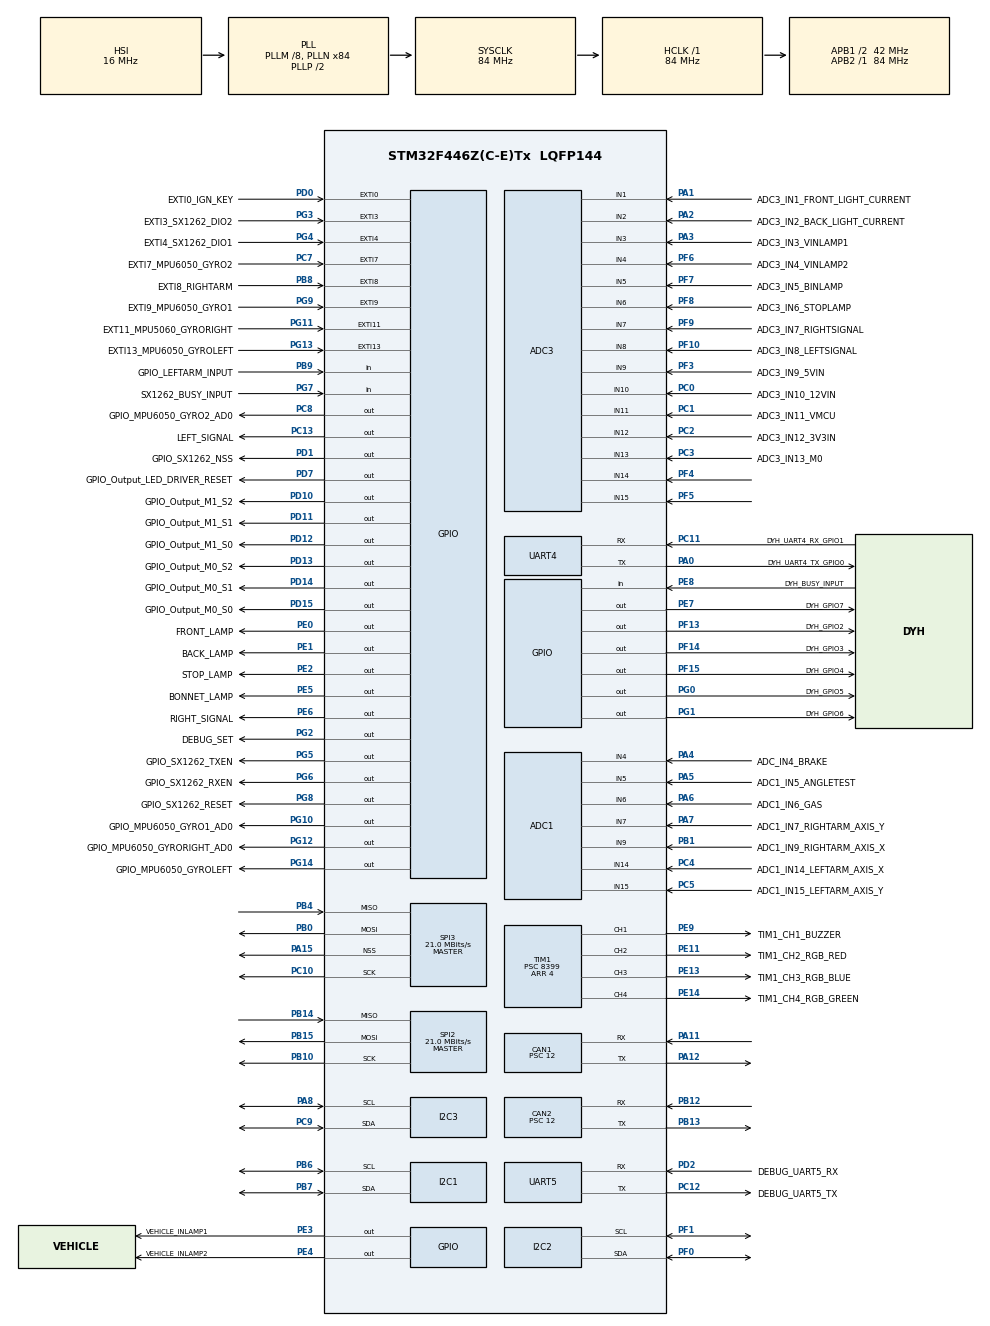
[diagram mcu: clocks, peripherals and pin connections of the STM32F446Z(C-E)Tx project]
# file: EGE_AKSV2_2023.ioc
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ADC1.Channel-1\#ChannelRegularConversion=ADC_CHANNEL_4
ADC1.Channel-2\#ChannelRegularConversion=ADC_CHANNEL_4
ADC1.Channel-3\#ChannelRegularConversion=ADC_CHANNEL_4
ADC1.Channel-4\#ChannelRegularConversion=ADC_CHANNEL_4
ADC1.Channel-5\#ChannelRegularConversion=ADC_CHANNEL_4
ADC1.Channel-6\#ChannelRegularConversion=ADC_CHANNEL_4
ADC1.Channel-7\#ChannelRegularConversion=ADC_CHANNEL_4
ADC1.ContinuousConvMode=DISABLE
ADC1.NbrOfConversion=7
ADC1.NbrOfConversionFlag=1
ADC1.Rank-1\#ChannelRegularConversion=1
ADC1.Rank-2\#ChannelRegularConversion=2
ADC1.Rank-3\#ChannelRegularConversion=3
ADC1.Rank-4\#ChannelRegularConversion=4
ADC1.Rank-5\#ChannelRegularConversion=5
ADC1.Rank-6\#ChannelRegularConversion=6
ADC1.Rank-7\#ChannelRegularConversion=7
ADC1.SamplingTime-1\#ChannelRegularConversion=ADC_SAMPLETIME_28CYCLES
ADC1.SamplingTime-2\#ChannelRegularConversion=ADC_SAMPLETIME_3CYCLES
ADC1.SamplingTime-3\#ChannelRegularConversion=ADC_SAMPLETIME_3CYCLES
ADC1.SamplingTime-4\#ChannelRegularConversion=ADC_SAMPLETIME_3CYCLES
ADC1.SamplingTime-5\#ChannelRegularConversion=ADC_SAMPLETIME_3CYCLES
ADC1.SamplingTime-6\#ChannelRegularConversion=ADC_SAMPLETIME_3CYCLES
ADC1.SamplingTime-7\#ChannelRegularConversion=ADC_SAMPLETIME_3CYCLES
ADC1.ScanConvMode=ENABLE
ADC1.master=1
ADC3.Channel-1\#ChannelRegularConversion=ADC_CHANNEL_1
ADC3.Channel-10\#ChannelRegularConversion=ADC_CHANNEL_1
ADC3.Channel-11\#ChannelRegularConversion=ADC_CHANNEL_1
ADC3.Channel-12\#ChannelRegularConversion=ADC_CHANNEL_1
ADC3.Channel-13\#ChannelRegularConversion=ADC_CHANNEL_1
ADC3.Channel-14\#ChannelRegularConversion=ADC_CHANNEL_1
ADC3.Channel-15\#ChannelRegularConversion=ADC_CHANNEL_1
ADC3.Channel-2\#ChannelRegularConversion=ADC_CHANNEL_1
ADC3.Channel-3\#ChannelRegularConversion=ADC_CHANNEL_1
ADC3.Channel-4\#ChannelRegularConversion=ADC_CHANNEL_1
ADC3.Channel-5\#ChannelRegularConversion=ADC_CHANNEL_1
ADC3.Channel-6\#ChannelRegularConversion=ADC_CHANNEL_1
ADC3.Channel-7\#ChannelRegularConversion=ADC_CHANNEL_1
ADC3.Channel-8\#ChannelRegularConversion=ADC_CHANNEL_1
ADC3.Channel-9\#ChannelRegularConversion=ADC_CHANNEL_1
ADC3.ContinuousConvMode=DISABLE
ADC3.NbrOfConversion=15
ADC3.NbrOfConversionFlag=1
ADC3.Rank-1\#ChannelRegularConversion=1
ADC3.Rank-10\#ChannelRegularConversion=10
ADC3.Rank-11\#ChannelRegularConversion=11
ADC3.Rank-12\#ChannelRegularConversion=12
ADC3.Rank-13\#ChannelRegularConversion=13
ADC3.Rank-14\#ChannelRegularConversion=14
ADC3.Rank-15\#ChannelRegularConversion=15
ADC3.Rank-2\#ChannelRegularConversion=2
ADC3.Rank-3\#ChannelRegularConversion=3
ADC3.Rank-4\#ChannelRegularConversion=4
ADC3.Rank-5\#ChannelRegularConversion=5
ADC3.Rank-6\#ChannelRegularConversion=6
ADC3.Rank-7\#ChannelRegularConversion=7
ADC3.Rank-8\#ChannelRegularConversion=8
ADC3.Rank-9\#ChannelRegularConversion=9
ADC3.SamplingTime-1\#ChannelRegularConversion=ADC_SAMPLETIME_3CYCLES
ADC3.SamplingTime-10\#ChannelRegularConversion=ADC_SAMPLETIME_3CYCLES
ADC3.SamplingTime-11\#ChannelRegularConversion=ADC_SAMPLETIME_3CYCLES
ADC3.SamplingTime-12\#ChannelRegularConversion=ADC_SAMPLETIME_3CYCLES
ADC3.SamplingTime-13\#ChannelRegularConversion=ADC_SAMPLETIME_3CYCLES
ADC3.SamplingTime-14\#ChannelRegularConversion=ADC_SAMPLETIME_3CYCLES
ADC3.SamplingTime-15\#ChannelRegularConversion=ADC_SAMPLETIME_3CYCLES
ADC3.SamplingTime-2\#ChannelRegularConversion=ADC_SAMPLETIME_3CYCLES
ADC3.SamplingTime-3\#ChannelRegularConversion=ADC_SAMPLETIME_3CYCLES
ADC3.SamplingTime-4\#ChannelRegularConversion=ADC_SAMPLETIME_3CYCLES
ADC3.SamplingTime-5\#ChannelRegularConversion=ADC_SAMPLETIME_3CYCLES
ADC3.SamplingTime-6\#ChannelRegularConversion=ADC_SAMPLETIME_3CYCLES
ADC3.SamplingTime-7\#ChannelRegularConversion=ADC_SAMPLETIME_3CYCLES
ADC3.SamplingTime-8\#ChannelRegularConversion=ADC_SAMPLETIME_3CYCLES
ADC3.SamplingTime-9\#ChannelRegularConversion=ADC_SAMPLETIME_3CYCLES
ADC3.ScanConvMode=ENABLE
CAN1.BS1=CAN_BS1_11TQ
CAN1.BS2=CAN_BS2_2TQ
CAN1.CalculateBaudRate=250000
CAN1.CalculateTimeBit=4000
CAN1.CalculateTimeQuantum=285.7142857142857
CAN1.NART=ENABLE
CAN1.Prescaler=12
CAN2.BS1=CAN_BS1_11TQ
CAN2.BS2=CAN_BS2_2TQ
CAN2.CalculateBaudRate=250000
CAN2.CalculateTimeBit=4000
CAN2.CalculateTimeQuantum=285.7142857142857
CAN2.NART=ENABLE
CAN2.Prescaler=12
FREERTOS.Tasks01=defaultTask,24,128,StartDefaultTask,Default,NULL,Dynamic,NULL,NULL
Mcu.Family=STM32F4
Mcu.Name=STM32F446Z(C-E)Tx
Mcu.Package=LQFP144
NVIC.CAN1_RX0_IRQn=true\:5\:0\:false\:false\:true\:true\:true\:true\:true
NVIC.CAN1_RX1_IRQn=true\:5\:0\:false\:false\:true\:true\:true\:true\:true
NVIC.CAN1_SCE_IRQn=true\:5\:0\:false\:false\:true\:true\:true\:true\:true
NVIC.CAN1_TX_IRQn=true\:5\:0\:false\:false\:true\:true\:true\:true\:true
NVIC.EXTI0_IRQn=true\:5\:0\:false\:false\:true\:true\:true\:true\:true
NVIC.EXTI15_10_IRQn=true\:5\:0\:false\:false\:true\:true\:true\:true\:true
NVIC.EXTI3_IRQn=true\:5\:0\:false\:false\:true\:true\:true\:true\:true
NVIC.EXTI4_IRQn=true\:5\:0\:false\:false\:true\:true\:true\:true\:true
NVIC.EXTI9_5_IRQn=true\:5\:0\:false\:false\:true\:true\:true\:true\:true
NVIC.PriorityGroup=NVIC_PRIORITYGROUP_4
PA0-WKUP.GPIO_Label=DYH_UART4_TX_GPIO0
PA0-WKUP.Mode=Asynchronous
PA0-WKUP.Signal=UART4_TX
PA1.GPIO_Label=ADC3_IN1_FRONT_LIGHT_CURRENT
PA1.Signal=ADCx_IN1
PA11.Mode=CAN_Activate
PA11.Signal=CAN1_RX
PA12.Mode=CAN_Activate
PA12.Signal=CAN1_TX
PA13.Mode=Serial_Wire
PA13.Signal=SYS_JTMS-SWDIO
PA14.Mode=Serial_Wire
PA14.Signal=SYS_JTCK-SWCLK
PA15.Mode=NSS_Signal_Hard_Output
PA15.Signal=SPI3_NSS
PA2.GPIO_Label=ADC3_IN2_BACK_LIGHT_CURRENT
PA2.Signal=ADCx_IN2
PA3.GPIO_Label=ADC3_IN3_VINLAMP1
PA3.Signal=ADCx_IN3
PA4.GPIO_Label=ADC_IN4_BRAKE
PA4.Signal=ADCx_IN4
PA5.GPIO_Label=ADC1_IN5_ANGLETEST
PA5.Signal=ADCx_IN5
PA6.GPIO_Label=ADC1_IN6_GAS
PA6.Signal=ADCx_IN6
PA7.GPIO_Label=ADC1_IN7_RIGHTARM_AXIS_Y
PA7.Signal=ADCx_IN7
PA8.Mode=I2C
PA8.Signal=I2C3_SCL
PB0.Mode=Full_Duplex_Master
PB0.Signal=SPI3_MOSI
PB1.GPIO_Label=ADC1_IN9_RIGHTARM_AXIS_X
PB1.Signal=ADCx_IN9
PB10.Mode=Full_Duplex_Master
PB10.Signal=SPI2_SCK
PB12.Mode=CAN_Activate
PB12.Signal=CAN2_RX
PB13.Mode=CAN_Activate
PB13.Signal=CAN2_TX
PB14.Mode=Full_Duplex_Master
PB14.Signal=SPI2_MISO
PB15.Mode=Full_Duplex_Master
PB15.Signal=SPI2_MOSI
PB4.Mode=Full_Duplex_Master
PB4.Signal=SPI3_MISO
PB6.Mode=I2C
PB6.Signal=I2C1_SCL
PB7.Mode=I2C
PB7.Signal=I2C1_SDA
PB8.GPIO_Label=EXTI8_RIGHTARM
PB8.Signal=GPXTI8
PB9.GPIO_Label=GPIO_LEFTARM_INPUT
PB9.Signal=GPIO_Input
PC0.GPIO_Label=ADC3_IN10_12VIN
PC0.Signal=ADCx_IN10
PC1.GPIO_Label=ADC3_IN11_VMCU
PC1.Signal=ADCx_IN11
PC10.Mode=Full_Duplex_Master
PC10.Signal=SPI3_SCK
PC11.GPIO_Label=DYH_UART4_RX_GPIO1
PC11.Mode=Asynchronous
PC11.Signal=UART4_RX
PC12.GPIO_Label=DEBUG_UART5_TX
PC12.Mode=Asynchronous
PC12.Signal=UART5_TX
PC13.GPIO_Label=LEFT_SIGNAL
PC13.Signal=GPIO_Output
PC14-OSC32_IN.Mode=LSE-External-Oscillator
PC14-OSC32_IN.Signal=RCC_OSC32_IN
PC15-OSC32_OUT.Mode=LSE-External-Oscillator
PC15-OSC32_OUT.Signal=RCC_OSC32_OUT
PC2.GPIO_Label=ADC3_IN12_3V3IN
PC2.Signal=ADCx_IN12
PC3.GPIO_Label=ADC3_IN13_M0
PC3.Signal=ADCx_IN13
PC4.GPIO_Label=ADC1_IN14_LEFTARM_AXIS_X
PC4.Signal=ADCx_IN14
PC5.GPIO_Label=ADC1_IN15_LEFTARM_AXIS_Y
PC5.Signal=ADCx_IN15
PC7.GPIO_Label=EXTI7_MPU6050_GYRO2
PC7.Signal=GPXTI7
PC8.GPIO_Label=GPIO_MPU6050_GYRO2_AD0
PC8.Signal=GPIO_Output
PC9.Mode=I2C
PC9.Signal=I2C3_SDA
PD0.GPIO_Label=EXTI0_IGN_KEY
PD0.Signal=GPXTI0
PD1.GPIO_Label=GPIO_SX1262_NSS
PD1.Signal=GPIO_Output
PD10.GPIO_Label=GPIO_Output_M1_S2
PD10.Signal=GPIO_Output
PD11.GPIO_Label=GPIO_Output_M1_S1
PD11.Signal=GPIO_Output
PD12.GPIO_Label=GPIO_Output_M1_S0
PD12.Signal=GPIO_Output
PD13.GPIO_Label=GPIO_Output_M0_S2
PD13.Signal=GPIO_Output
PD14.GPIO_Label=GPIO_Output_M0_S1
PD14.Signal=GPIO_Output
PD15.GPIO_Label=GPIO_Output_M0_S0
PD15.Signal=GPIO_Output
PD2.GPIO_Label=DEBUG_UART5_RX
PD2.Mode=Asynchronous
PD2.Signal=UART5_RX
PD7.GPIO_Label=GPIO_Output_LED_DRIVER_RESET
PD7.Signal=GPIO_Output
PE0.GPIO_Label=FRONT_LAMP
PE0.Signal=GPIO_Output
PE1.GPIO_Label=BACK_LAMP
PE1.Signal=GPIO_Output
PE11.GPIO_Label=TIM1_CH2_RGB_RED
PE11.Signal=S_TIM1_CH2
PE13.GPIO_Label=TIM1_CH3_RGB_BLUE
PE13.Signal=S_TIM1_CH3
PE14.GPIO_Label=TIM1_CH4_RGB_GREEN
PE14.Signal=S_TIM1_CH4
PE2.GPIO_Label=STOP_LAMP
PE2.Signal=GPIO_Output
PE3.GPIO_Label=VEHICLE_INLAMP1
PE3.Signal=GPIO_Output
PE4.GPIO_Label=VEHICLE_INLAMP2
PE4.Signal=GPIO_Output
PE5.GPIO_Label=BONNET_LAMP
PE5.Signal=GPIO_Output
PE6.GPIO_Label=RIGHT_SIGNAL
PE6.Signal=GPIO_Output
PE7.GPIO_Label=DYH_GPIO7
PE7.Signal=GPIO_Output
PE8.GPIO_Label=DYH_BUSY_INPUT
PE8.Signal=GPIO_Input
PE9.GPIO_Label=TIM1_CH1_BUZZER
PE9.Signal=S_TIM1_CH1
PF0.Mode=I2C
PF0.Signal=I2C2_SDA
PF1.Mode=I2C
PF1.Signal=I2C2_SCL
PF10.GPIO_Label=ADC3_IN8_LEFTSIGNAL
PF10.Mode=IN8
PF10.Signal=ADC3_IN8
PF13.GPIO_Label=DYH_GPIO2
PF13.Signal=GPIO_Output
PF14.GPIO_Label=DYH_GPIO3
PF14.Signal=GPIO_Output
PF15.GPIO_Label=DYH_GPIO4
PF15.Signal=GPIO_Output
PF3.GPIO_Label=ADC3_IN9_5VIN
PF3.Mode=IN9
PF3.Signal=ADC3_IN9
PF4.Mode=IN14
PF4.Signal=ADC3_IN14
PF5.Mode=IN15
PF5.Signal=ADC3_IN15
PF6.GPIO_Label=ADC3_IN4_VINLAMP2
PF6.Mode=IN4
PF6.Signal=ADC3_IN4
PF7.GPIO_Label=ADC3_IN5_BINLAMP
PF7.Mode=IN5
PF7.Signal=ADC3_IN5
PF8.GPIO_Label=ADC3_IN6_STOPLAMP
PF8.Mode=IN6
PF8.Signal=ADC3_IN6
PF9.GPIO_Label=ADC3_IN7_RIGHTSIGNAL
PF9.Mode=IN7
PF9.Signal=ADC3_IN7
PG0.GPIO_Label=DYH_GPIO5
PG0.Signal=GPIO_Output
PG1.GPIO_Label=DYH_GPIO6
PG1.Signal=GPIO_Output
PG10.GPIO_Label=GPIO_MPU6050_GYRO1_AD0
PG10.Signal=GPIO_Output
PG11.GPIO_Label=EXT11_MPU5060_GYRORIGHT
PG11.Signal=GPXTI11
PG12.GPIO_Label=GPIO_MPU6050_GYRORIGHT_AD0
PG12.Signal=GPIO_Output
PG13.GPIO_Label=EXTI13_MPU6050_GYROLEFT
PG13.Signal=GPXTI13
PG14.GPIO_Label=GPIO_MPU6050_GYROLEFT
PG14.Signal=GPIO_Output
PG2.GPIO_Label=DEBUG_SET
PG2.Signal=GPIO_Output
PG3.GPIO_Label=EXTI3_SX1262_DIO2
PG3.Signal=GPXTI3
PG4.GPIO_Label=EXTI4_SX1262_DIO1
PG4.Signal=GPXTI4
PG5.GPIO_Label=GPIO_SX1262_TXEN
PG5.Signal=GPIO_Output
PG6.GPIO_Label=GPIO_SX1262_RXEN
PG6.Signal=GPIO_Output
PG7.GPIO_Label=SX1262_BUSY_INPUT
PG7.Signal=GPIO_Input
PG8.GPIO_Label=GPIO_SX1262_RESET
PG8.Signal=GPIO_Output
PG9.GPIO_Label=EXTI9_MPU6050_GYRO1
PG9.Signal=GPXTI9
PH0-OSC_IN.Mode=HSE-External-Oscillator
PH0-OSC_IN.Signal=RCC_OSC_IN
PH1-OSC_OUT.Mode=HSE-External-Oscillator
PH1-OSC_OUT.Signal=RCC_OSC_OUT
ProjectManager.HeapSize=0x2000
ProjectManager.StackSize=0x4000
ProjectManager.TargetToolchain=STM32CubeIDE
RCC.AHBFreq_Value=84000000
RCC.APB1CLKDivider=RCC_HCLK_DIV2
RCC.APB1Freq_Value=42000000
RCC.APB1TimFreq_Value=84000000
RCC.APB2Freq_Value=84000000
RCC.APB2TimFreq_Value=84000000
RCC.CortexFreq_Value=84000000
RCC.HCLKFreq_Value=84000000
RCC.PLLM=8
RCC.PLLN=84
RCC.SYSCLKFreq_VALUE=84000000
RCC.SYSCLKSource=RCC_SYSCLKSOURCE_PLLCLK
RCC.USBFreq_Value=84000000
RCC.VCOOutputFreq_Value=168000000
SH.ADCx_IN1.0=ADC3_IN1,IN1
SH.ADCx_IN10.0=ADC3_IN10,IN10
SH.ADCx_IN11.0=ADC3_IN11,IN11
SH.ADCx_IN12.0=ADC3_IN12,IN12
SH.ADCx_IN13.0=ADC3_IN13,IN13
SH.ADCx_IN14.0=ADC1_IN14,IN14
SH.ADCx_IN15.0=ADC1_IN15,IN15
SH.ADCx_IN2.0=ADC3_IN2,IN2
SH.ADCx_IN3.0=ADC3_IN3,IN3
SH.ADCx_IN4.0=ADC1_IN4,IN4
SH.ADCx_IN5.0=ADC1_IN5,IN5
SH.ADCx_IN6.0=ADC1_IN6,IN6
SH.ADCx_IN7.0=ADC1_IN7,IN7
SH.ADCx_IN9.0=ADC1_IN9,IN9
SH.S_TIM1_CH1.0=TIM1_CH1,PWM Generation1 CH1
SH.S_TIM1_CH2.0=TIM1_CH2,PWM Generation2 CH2
SH.S_TIM1_CH3.0=TIM1_CH3,PWM Generation3 CH3
SH.S_TIM1_CH4.0=TIM1_CH4,PWM Generation4 CH4
SPI2.CalculateBaudRate=21.0 MBits/s
SPI2.Direction=SPI_DIRECTION_2LINES
SPI2.Mode=SPI_MODE_MASTER
SPI2.VirtualType=VM_MASTER
SPI3.CalculateBaudRate=21.0 MBits/s
SPI3.Direction=SPI_DIRECTION_2LINES
SPI3.Mode=SPI_MODE_MASTER
SPI3.VirtualNSS=VM_NSSHARD
SPI3.VirtualType=VM_MASTER
TIM1.Channel-PWM\ Generation1\ CH1=TIM_CHANNEL_1
TIM1.Channel-PWM\ Generation2\ CH2=TIM_CHANNEL_2
TIM1.Channel-PWM\ Generation3\ CH3=TIM_CHANNEL_3
TIM1.Channel-PWM\ Generation4\ CH4=TIM_CHANNEL_4
TIM1.Period=4
TIM1.Prescaler=8399
UART4.VirtualMode=Asynchronous
UART5.VirtualMode=Asynchronous
VP_CRC_VS_CRC.Mode=CRC_Activate
VP_FREERTOS_VS_CMSIS_V2.Mode=CMSIS_V2
VP_IWDG_VS_IWDG.Mode=IWDG_Activate
VP_RTC_VS_RTC_Activate.Mode=RTC_Enabled
VP_TIM1_VS_ClockSourceINT.Mode=Internal
VP_WWDG_VS_WWDG.Mode=WWDG_Activate
board=custom

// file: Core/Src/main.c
/* USER CODE BEGIN Header */
/**
  ******************************************************************************
  * @file           : main.c
  * @brief          : Main program body
  ******************************************************************************
  * @attention
  *
  * Copyright (c) 2023 STMicroelectronics.
  * All rights reserved.
  *
  * This software is licensed under terms that can be found in the LICENSE file
  * in the root directory of this software component.
  * If no LICENSE file comes with this software, it is provided AS-IS.
  *
  ******************************************************************************
  */
/* USER CODE END Header */
#include "main.h"
#include "cmsis_os.h"

ADC_HandleTypeDef hadc1;
ADC_HandleTypeDef hadc3;

CAN_HandleTypeDef hcan1;
CAN_HandleTypeDef hcan2;

CRC_HandleTypeDef hcrc;

I2C_HandleTypeDef hi2c1;
I2C_HandleTypeDef hi2c2;
I2C_HandleTypeDef hi2c3;

IWDG_HandleTypeDef hiwdg;

RTC_HandleTypeDef hrtc;

SPI_HandleTypeDef hspi2;
SPI_HandleTypeDef hspi3;

TIM_HandleTypeDef htim1;

UART_HandleTypeDef huart4;
UART_HandleTypeDef huart5;

WWDG_HandleTypeDef hwwdg;

/* Definitions for defaultTask */
osThreadId_t defaultTaskHandle;
const osThreadAttr_t defaultTask_attributes = {
  .name = "defaultTask",
  .stack_size = 128 * 4,
  .priority = (osPriority_t) osPriorityNormal,
};

void SystemClock_Config(void);
static void MX_GPIO_Init(void);
static void MX_ADC1_Init(void);
static void MX_ADC3_Init(void);
static void MX_CAN1_Init(void);
static void MX_CAN2_Init(void);
static void MX_I2C1_Init(void);
static void MX_I2C2_Init(void);
static void MX_I2C3_Init(void);
static void MX_SPI2_Init(void);
static void MX_SPI3_Init(void);
static void MX_TIM1_Init(void);
static void MX_UART4_Init(void);
static void MX_UART5_Init(void);
static void MX_CRC_Init(void);
static void MX_IWDG_Init(void);
static void MX_RTC_Init(void);
static void MX_WWDG_Init(void);
void StartDefaultTask(void *argument);

int main(void)
{

  /* MCU Configuration--------------------------------------------------------*/

  /* Reset of all peripherals, Initializes the Flash interface and the Systick. */
  HAL_Init();

  /* Configure the system clock */
  SystemClock_Config();

  /* Initialize all configured peripherals */
  MX_GPIO_Init();
  MX_ADC1_Init();
  MX_ADC3_Init();
  MX_CAN1_Init();
  MX_CAN2_Init();
  MX_I2C1_Init();
  MX_I2C2_Init();
  MX_I2C3_Init();
  MX_SPI2_Init();
  MX_SPI3_Init();
  MX_TIM1_Init();
  MX_UART4_Init();
  MX_UART5_Init();
  MX_CRC_Init();
 //MX_IWDG_Init();
  MX_RTC_Init();
 // MX_WWDG_Init();
  /* USER CODE BEGIN 2 */

  MAIN_App(); /* JUMP INTO BODY CONTROL MODULE */

  /* USER CODE END 2 */

  /* Init scheduler */
  osKernelInitialize();

  /* Create the thread(s) */
  /* creation of defaultTask */
  defaultTaskHandle = osThreadNew(StartDefaultTask, NULL, &defaultTask_attributes);

  /* Start scheduler */
  osKernelStart();
  /* We should never get here as control is now taken by the scheduler */
  /* Infinite loop */
  while (1)
  {

  }
}

void SystemClock_Config(void)
{
  RCC_OscInitTypeDef RCC_OscInitStruct = {0};
  RCC_ClkInitTypeDef RCC_ClkInitStruct = {0};

  /** Configure the main internal regulator output voltage
  */
  __HAL_RCC_PWR_CLK_ENABLE();
  __HAL_PWR_VOLTAGESCALING_CONFIG(PWR_REGULATOR_VOLTAGE_SCALE3);

  /** Initializes the RCC Oscillators according to the specified parameters
  * in the RCC_OscInitTypeDef structure.
  */
  RCC_OscInitStruct.OscillatorType = RCC_OSCILLATORTYPE_HSI|RCC_OSCILLATORTYPE_LSI;
  RCC_OscInitStruct.LSEState = RCC_LSE_ON;
  RCC_OscInitStruct.HSIState = RCC_HSI_ON;
  RCC_OscInitStruct.HSICalibrationValue = RCC_HSICALIBRATION_DEFAULT;
  RCC_OscInitStruct.LSIState = RCC_LSI_ON;
  RCC_OscInitStruct.PLL.PLLState = RCC_PLL_ON;
  RCC_OscInitStruct.PLL.PLLSource = RCC_PLLSOURCE_HSI;
  RCC_OscInitStruct.PLL.PLLM = 8;
  RCC_OscInitStruct.PLL.PLLN = 84;
  RCC_OscInitStruct.PLL.PLLP = RCC_PLLP_DIV2;
  RCC_OscInitStruct.PLL.PLLQ = 2;
  RCC_OscInitStruct.PLL.PLLR = 2;
  if (HAL_RCC_OscConfig(&RCC_OscInitStruct) != HAL_OK)
  {
    Error_Handler();
  }

  /** Initializes the CPU, AHB and APB buses clocks
  */
  RCC_ClkInitStruct.ClockType = RCC_CLOCKTYPE_HCLK|RCC_CLOCKTYPE_SYSCLK
                              |RCC_CLOCKTYPE_PCLK1|RCC_CLOCKTYPE_PCLK2;
  RCC_ClkInitStruct.SYSCLKSource = RCC_SYSCLKSOURCE_PLLCLK;
  RCC_ClkInitStruct.AHBCLKDivider = RCC_SYSCLK_DIV1;
  RCC_ClkInitStruct.APB1CLKDivider = RCC_HCLK_DIV2;
  RCC_ClkInitStruct.APB2CLKDivider = RCC_HCLK_DIV1;

  if (HAL_RCC_ClockConfig(&RCC_ClkInitStruct, FLASH_LATENCY_2) != HAL_OK)
  {
    Error_Handler();
  }
}

static void MX_ADC1_Init(void)
{

  ADC_ChannelConfTypeDef sConfig = {0};

  /** Configure the global features of the ADC (Clock, Resolution, Data Alignment and number of conversion)
  */
  hadc1.Instance = ADC1;
  hadc1.Init.ClockPrescaler = ADC_CLOCK_SYNC_PCLK_DIV4;
  hadc1.Init.Resolution = ADC_RESOLUTION_12B;
  hadc1.Init.ScanConvMode = ENABLE;
  hadc1.Init.ContinuousConvMode = DISABLE;
  hadc1.Init.DiscontinuousConvMode = DISABLE;
  hadc1.Init.ExternalTrigConvEdge = ADC_EXTERNALTRIGCONVEDGE_NONE;
  hadc1.Init.ExternalTrigConv = ADC_SOFTWARE_START;
  hadc1.Init.DataAlign = ADC_DATAALIGN_RIGHT;
  hadc1.Init.NbrOfConversion = 7;
  hadc1.Init.DMAContinuousRequests = DISABLE;
  hadc1.Init.EOCSelection = ADC_EOC_SINGLE_CONV;
  if (HAL_ADC_Init(&hadc1) != HAL_OK)
  {
    Error_Handler();
  }

  /** Configure for the selected ADC regular channel its corresponding rank in the sequencer and its sample time.
  */
  sConfig.Channel = ADC_CHANNEL_4;
  sConfig.Rank = 1;
  sConfig.SamplingTime = ADC_SAMPLETIME_28CYCLES;
  if (HAL_ADC_ConfigChannel(&hadc1, &sConfig) != HAL_OK)
  {
    Error_Handler();
  }

  /** Configure for the selected ADC regular channel its corresponding rank in the sequencer and its sample time.
  */
  sConfig.Rank = 2;
  sConfig.SamplingTime = ADC_SAMPLETIME_3CYCLES;
  if (HAL_ADC_ConfigChannel(&hadc1, &sConfig) != HAL_OK)
  {
    Error_Handler();
  }

  /** Configure for the selected ADC regular channel its corresponding rank in the sequencer and its sample time.
  */
  sConfig.Rank = 3;
  if (HAL_ADC_ConfigChannel(&hadc1, &sConfig) != HAL_OK)
  {
    Error_Handler();
  }

  /** Configure for the selected ADC regular channel its corresponding rank in the sequencer and its sample time.
  */
  sConfig.Rank = 4;
  if (HAL_ADC_ConfigChannel(&hadc1, &sConfig) != HAL_OK)
  {
    Error_Handler();
  }

  /** Configure for the selected ADC regular channel its corresponding rank in the sequencer and its sample time.
  */
  sConfig.Rank = 5;
  if (HAL_ADC_ConfigChannel(&hadc1, &sConfig) != HAL_OK)
  {
    Error_Handler();
  }

  /** Configure for the selected ADC regular channel its corresponding rank in the sequencer and its sample time.
  */
  sConfig.Rank = 6;
  if (HAL_ADC_ConfigChannel(&hadc1, &sConfig) != HAL_OK)
  {
    Error_Handler();
  }

  /** Configure for the selected ADC regular channel its corresponding rank in the sequencer and its sample time.
  */
  sConfig.Rank = 7;
  if (HAL_ADC_ConfigChannel(&hadc1, &sConfig) != HAL_OK)
  {
    Error_Handler();
  }

}

static void MX_ADC3_Init(void)
{

  ADC_ChannelConfTypeDef sConfig = {0};

  /** Configure the global features of the ADC (Clock, Resolution, Data Alignment and number of conversion)
  */
  hadc3.Instance = ADC3;
  hadc3.Init.ClockPrescaler = ADC_CLOCK_SYNC_PCLK_DIV4;
  hadc3.Init.Resolution = ADC_RESOLUTION_12B;
  hadc3.Init.ScanConvMode = ENABLE;
  hadc3.Init.ContinuousConvMode = DISABLE;
  hadc3.Init.DiscontinuousConvMode = DISABLE;
  hadc3.Init.ExternalTrigConvEdge = ADC_EXTERNALTRIGCONVEDGE_NONE;
  hadc3.Init.ExternalTrigConv = ADC_SOFTWARE_START;
  hadc3.Init.DataAlign = ADC_DATAALIGN_RIGHT;
  hadc3.Init.NbrOfConversion = 15;
  hadc3.Init.DMAContinuousRequests = DISABLE;
  hadc3.Init.EOCSelection = ADC_EOC_SINGLE_CONV;
  if (HAL_ADC_Init(&hadc3) != HAL_OK)
  {
    Error_Handler();
  }

  /** Configure for the selected ADC regular channel its corresponding rank in the sequencer and its sample time.
  */
  sConfig.Channel = ADC_CHANNEL_1;
  sConfig.Rank = 1;
  sConfig.SamplingTime = ADC_SAMPLETIME_3CYCLES;
  if (HAL_ADC_ConfigChannel(&hadc3, &sConfig) != HAL_OK)
  {
    Error_Handler();
  }

  /** Configure for the selected ADC regular channel its corresponding rank in the sequencer and its sample time.
  */
  sConfig.Rank = 2;
  if (HAL_ADC_ConfigChannel(&hadc3, &sConfig) != HAL_OK)
  {
    Error_Handler();
  }

  /** Configure for the selected ADC regular channel its corresponding rank in the sequencer and its sample time.
  */
  sConfig.Rank = 3;
  if (HAL_ADC_ConfigChannel(&hadc3, &sConfig) != HAL_OK)
  {
    Error_Handler();
  }

  /** Configure for the selected ADC regular channel its corresponding rank in the sequencer and its sample time.
  */
  sConfig.Rank = 4;
  if (HAL_ADC_ConfigChannel(&hadc3, &sConfig) != HAL_OK)
  {
    Error_Handler();
  }

  /** Configure for the selected ADC regular channel its corresponding rank in the sequencer and its sample time.
  */
  sConfig.Rank = 5;
  if (HAL_ADC_ConfigChannel(&hadc3, &sConfig) != HAL_OK)
  {
    Error_Handler();
  }

  /** Configure for the selected ADC regular channel its corresponding rank in the sequencer and its sample time.
  */
  sConfig.Rank = 6;
  if (HAL_ADC_ConfigChannel(&hadc3, &sConfig) != HAL_OK)
  {
    Error_Handler();
  }

  /** Configure for the selected ADC regular channel its corresponding rank in the sequencer and its sample time.
  */
  sConfig.Rank = 7;
  if (HAL_ADC_ConfigChannel(&hadc3, &sConfig) != HAL_OK)
  {
    Error_Handler();
  }

  /** Configure for the selected ADC regular channel its corresponding rank in the sequencer and its sample time.
  */
  sConfig.Rank = 8;
  if (HAL_ADC_ConfigChannel(&hadc3, &sConfig) != HAL_OK)
  {
    Error_Handler();
  }

  /** Configure for the selected ADC regular channel its corresponding rank in the sequencer and its sample time.
  */
  sConfig.Rank = 9;
  if (HAL_ADC_ConfigChannel(&hadc3, &sConfig) != HAL_OK)
  {
    Error_Handler();
  }

  /** Configure for the selected ADC regular channel its corresponding rank in the sequencer and its sample time.
  */
  sConfig.Rank = 10;
  if (HAL_ADC_ConfigChannel(&hadc3, &sConfig) != HAL_OK)
  {
    Error_Handler();
  }

  /** Configure for the selected ADC regular channel its corresponding rank in the sequencer and its sample time.
  */
  sConfig.Rank = 11;
  if (HAL_ADC_ConfigChannel(&hadc3, &sConfig) != HAL_OK)
  {
    Error_Handler();
  }

  /** Configure for the selected ADC regular channel its corresponding rank in the sequencer and its sample time.
  */
  sConfig.Rank = 12;
  if (HAL_ADC_ConfigChannel(&hadc3, &sConfig) != HAL_OK)
  {
    Error_Handler();
  }

  /** Configure for the selected ADC regular channel its corresponding rank in the sequencer and its sample time.
  */
  sConfig.Rank = 13;
  if (HAL_ADC_ConfigChannel(&hadc3, &sConfig) != HAL_OK)
  {
    Error_Handler();
  }

  /** Configure for the selected ADC regular channel its corresponding rank in the sequencer and its sample time.
  */
  sConfig.Rank = 14;
  if (HAL_ADC_ConfigChannel(&hadc3, &sConfig) != HAL_OK)
  {
    Error_Handler();
  }

  /** Configure for the selected ADC regular channel its corresponding rank in the sequencer and its sample time.
  */
  sConfig.Rank = 15;
  if (HAL_ADC_ConfigChannel(&hadc3, &sConfig) != HAL_OK)
  {
    Error_Handler();
  }

}

static void MX_CAN1_Init(void)
{

  hcan1.Instance = CAN1;
  hcan1.Init.Prescaler = 12;
  hcan1.Init.Mode = CAN_MODE_NORMAL;
  hcan1.Init.SyncJumpWidth = CAN_SJW_1TQ;
  hcan1.Init.TimeSeg1 = CAN_BS1_11TQ;
  hcan1.Init.TimeSeg2 = CAN_BS2_2TQ;
  hcan1.Init.TimeTriggeredMode = DISABLE;
  hcan1.Init.AutoBusOff = DISABLE;
  hcan1.Init.AutoWakeUp = DISABLE;
  hcan1.Init.AutoRetransmission = ENABLE;
  hcan1.Init.ReceiveFifoLocked = DISABLE;
  hcan1.Init.TransmitFifoPriority = DISABLE;
  if (HAL_CAN_Init(&hcan1) != HAL_OK)
  {
    Error_Handler();
  }

}

static void MX_CAN2_Init(void)
{

  hcan2.Instance = CAN2;
  hcan2.Init.Prescaler = 12;
  hcan2.Init.Mode = CAN_MODE_NORMAL;
  hcan2.Init.SyncJumpWidth = CAN_SJW_1TQ;
  hcan2.Init.TimeSeg1 = CAN_BS1_11TQ;
  hcan2.Init.TimeSeg2 = CAN_BS2_2TQ;
  hcan2.Init.TimeTriggeredMode = DISABLE;
  hcan2.Init.AutoBusOff = DISABLE;
  hcan2.Init.AutoWakeUp = DISABLE;
  hcan2.Init.AutoRetransmission = ENABLE;
  hcan2.Init.ReceiveFifoLocked = DISABLE;
  hcan2.Init.TransmitFifoPriority = DISABLE;
  if (HAL_CAN_Init(&hcan2) != HAL_OK)
  {
    Error_Handler();
  }

}

static void MX_CRC_Init(void)
{

  hcrc.Instance = CRC;
  if (HAL_CRC_Init(&hcrc) != HAL_OK)
  {
    Error_Handler();
  }

}

static void MX_I2C1_Init(void)
{

  hi2c1.Instance = I2C1;
  hi2c1.Init.ClockSpeed = 100000;
  hi2c1.Init.DutyCycle = I2C_DUTYCYCLE_2;
  hi2c1.Init.OwnAddress1 = 0;
  hi2c1.Init.AddressingMode = I2C_ADDRESSINGMODE_7BIT;
  hi2c1.Init.DualAddressMode = I2C_DUALADDRESS_DISABLE;
  hi2c1.Init.OwnAddress2 = 0;
  hi2c1.Init.GeneralCallMode = I2C_GENERALCALL_DISABLE;
  hi2c1.Init.NoStretchMode = I2C_NOSTRETCH_DISABLE;
  if (HAL_I2C_Init(&hi2c1) != HAL_OK)
  {
    Error_Handler();
  }

}

static void MX_I2C2_Init(void)
{

  hi2c2.Instance = I2C2;
  hi2c2.Init.ClockSpeed = 100000;
  hi2c2.Init.DutyCycle = I2C_DUTYCYCLE_2;
  hi2c2.Init.OwnAddress1 = 0;
  hi2c2.Init.AddressingMode = I2C_ADDRESSINGMODE_7BIT;
  hi2c2.Init.DualAddressMode = I2C_DUALADDRESS_DISABLE;
  hi2c2.Init.OwnAddress2 = 0;
  hi2c2.Init.GeneralCallMode = I2C_GENERALCALL_DISABLE;
  hi2c2.Init.NoStretchMode = I2C_NOSTRETCH_DISABLE;
  if (HAL_I2C_Init(&hi2c2) != HAL_OK)
  {
    Error_Handler();
  }

}

static void MX_I2C3_Init(void)
{

  hi2c3.Instance = I2C3;
  hi2c3.Init.ClockSpeed = 100000;
  hi2c3.Init.DutyCycle = I2C_DUTYCYCLE_2;
  hi2c3.Init.OwnAddress1 = 0;
  hi2c3.Init.AddressingMode = I2C_ADDRESSINGMODE_7BIT;
  hi2c3.Init.DualAddressMode = I2C_DUALADDRESS_DISABLE;
  hi2c3.Init.OwnAddress2 = 0;
  hi2c3.Init.GeneralCallMode = I2C_GENERALCALL_DISABLE;
  hi2c3.Init.NoStretchMode = I2C_NOSTRETCH_DISABLE;
  if (HAL_I2C_Init(&hi2c3) != HAL_OK)
  {
    Error_Handler();
  }

}

static void MX_IWDG_Init(void)
{

  hiwdg.Instance = IWDG;
  hiwdg.Init.Prescaler = IWDG_PRESCALER_4;
  hiwdg.Init.Reload = 4095;
  if (HAL_IWDG_Init(&hiwdg) != HAL_OK)
  {
    Error_Handler();
  }

}

static void MX_RTC_Init(void)
{

  /** Initialize RTC Only
  */
  hrtc.Instance = RTC;
  hrtc.Init.HourFormat = RTC_HOURFORMAT_24;
  hrtc.Init.AsynchPrediv = 127;
  hrtc.Init.SynchPrediv = 255;
  hrtc.Init.OutPut = RTC_OUTPUT_DISABLE;
  hrtc.Init.OutPutPolarity = RTC_OUTPUT_POLARITY_HIGH;
  hrtc.Init.OutPutType = RTC_OUTPUT_TYPE_OPENDRAIN;
  if (HAL_RTC_Init(&hrtc) != HAL_OK)
  {
    Error_Handler();
  }

}

static void MX_SPI2_Init(void)
{

  /* SPI2 parameter configuration*/
  hspi2.Instance = SPI2;
  hspi2.Init.Mode = SPI_MODE_MASTER;
  hspi2.Init.Direction = SPI_DIRECTION_2LINES;
  hspi2.Init.DataSize = SPI_DATASIZE_8BIT;
  hspi2.Init.CLKPolarity = SPI_POLARITY_LOW;
  hspi2.Init.CLKPhase = SPI_PHASE_1EDGE;
  hspi2.Init.NSS = SPI_NSS_SOFT;
  hspi2.Init.BaudRatePrescaler = SPI_BAUDRATEPRESCALER_2;
  hspi2.Init.FirstBit = SPI_FIRSTBIT_MSB;
  hspi2.Init.TIMode = SPI_TIMODE_DISABLE;
  hspi2.Init.CRCCalculation = SPI_CRCCALCULATION_DISABLE;
  hspi2.Init.CRCPolynomial = 10;
  if (HAL_SPI_Init(&hspi2) != HAL_OK)
  {
    Error_Handler();
  }

}

static void MX_SPI3_Init(void)
{

  /* SPI3 parameter configuration*/
  hspi3.Instance = SPI3;
  hspi3.Init.Mode = SPI_MODE_MASTER;
  hspi3.Init.Direction = SPI_DIRECTION_2LINES;
  hspi3.Init.DataSize = SPI_DATASIZE_8BIT;
  hspi3.Init.CLKPolarity = SPI_POLARITY_LOW;
  hspi3.Init.CLKPhase = SPI_PHASE_1EDGE;
  hspi3.Init.NSS = SPI_NSS_HARD_OUTPUT;
  hspi3.Init.BaudRatePrescaler = SPI_BAUDRATEPRESCALER_2;
  hspi3.Init.FirstBit = SPI_FIRSTBIT_MSB;
  hspi3.Init.TIMode = SPI_TIMODE_DISABLE;
  hspi3.Init.CRCCalculation = SPI_CRCCALCULATION_DISABLE;
  hspi3.Init.CRCPolynomial = 10;
  if (HAL_SPI_Init(&hspi3) != HAL_OK)
  {
    Error_Handler();
  }

}

static void MX_TIM1_Init(void)
{

  TIM_ClockConfigTypeDef sClockSourceConfig = {0};
  TIM_MasterConfigTypeDef sMasterConfig = {0};
  TIM_OC_InitTypeDef sConfigOC = {0};
  TIM_BreakDeadTimeConfigTypeDef sBreakDeadTimeConfig = {0};

  htim1.Instance = TIM1;
  htim1.Init.Prescaler = 8399;
  htim1.Init.CounterMode = TIM_COUNTERMODE_UP;
  htim1.Init.Period = 4;
  htim1.Init.ClockDivision = TIM_CLOCKDIVISION_DIV1;
  htim1.Init.RepetitionCounter = 0;
  htim1.Init.AutoReloadPreload = TIM_AUTORELOAD_PRELOAD_DISABLE;
  if (HAL_TIM_Base_Init(&htim1) != HAL_OK)
  {
    Error_Handler();
  }
  sClockSourceConfig.ClockSource = TIM_CLOCKSOURCE_INTERNAL;
  if (HAL_TIM_ConfigClockSource(&htim1, &sClockSourceConfig) != HAL_OK)
  {
    Error_Handler();
  }
  if (HAL_TIM_PWM_Init(&htim1) != HAL_OK)
  {
    Error_Handler();
  }
  sMasterConfig.MasterOutputTrigger = TIM_TRGO_RESET;
  sMasterConfig.MasterSlaveMode = TIM_MASTERSLAVEMODE_DISABLE;
  if (HAL_TIMEx_MasterConfigSynchronization(&htim1, &sMasterConfig) != HAL_OK)
  {
    Error_Handler();
  }
  sConfigOC.OCMode = TIM_OCMODE_PWM1;
  sConfigOC.Pulse = 0;
  sConfigOC.OCPolarity = TIM_OCPOLARITY_HIGH;
  sConfigOC.OCNPolarity = TIM_OCNPOLARITY_HIGH;
  sConfigOC.OCFastMode = TIM_OCFAST_DISABLE;
  sConfigOC.OCIdleState = TIM_OCIDLESTATE_RESET;
  sConfigOC.OCNIdleState = TIM_OCNIDLESTATE_RESET;
  if (HAL_TIM_PWM_ConfigChannel(&htim1, &sConfigOC, TIM_CHANNEL_1) != HAL_OK)
  {
    Error_Handler();
  }
  if (HAL_TIM_PWM_ConfigChannel(&htim1, &sConfigOC, TIM_CHANNEL_2) != HAL_OK)
  {
    Error_Handler();
  }
  if (HAL_TIM_PWM_ConfigChannel(&htim1, &sConfigOC, TIM_CHANNEL_3) != HAL_OK)
  {
    Error_Handler();
  }
  if (HAL_TIM_PWM_ConfigChannel(&htim1, &sConfigOC, TIM_CHANNEL_4) != HAL_OK)
  {
    Error_Handler();
  }
  sBreakDeadTimeConfig.OffStateRunMode = TIM_OSSR_DISABLE;
  sBreakDeadTimeConfig.OffStateIDLEMode = TIM_OSSI_DISABLE;
  sBreakDeadTimeConfig.LockLevel = TIM_LOCKLEVEL_OFF;
  sBreakDeadTimeConfig.DeadTime = 0;
  sBreakDeadTimeConfig.BreakState = TIM_BREAK_DISABLE;
  sBreakDeadTimeConfig.BreakPolarity = TIM_BREAKPOLARITY_HIGH;
  sBreakDeadTimeConfig.AutomaticOutput = TIM_AUTOMATICOUTPUT_DISABLE;
  if (HAL_TIMEx_ConfigBreakDeadTime(&htim1, &sBreakDeadTimeConfig) != HAL_OK)
  {
    Error_Handler();
  }
  HAL_TIM_MspPostInit(&htim1);

}

static void MX_UART4_Init(void)
{

  huart4.Instance = UART4;
  huart4.Init.BaudRate = 115200;
  huart4.Init.WordLength = UART_WORDLENGTH_8B;
  huart4.Init.StopBits = UART_STOPBITS_1;
  huart4.Init.Parity = UART_PARITY_NONE;
  huart4.Init.Mode = UART_MODE_TX_RX;
  huart4.Init.HwFlowCtl = UART_HWCONTROL_NONE;
  huart4.Init.OverSampling = UART_OVERSAMPLING_16;
  if (HAL_UART_Init(&huart4) != HAL_OK)
  {
    Error_Handler();
  }

}

static void MX_UART5_Init(void)
{

  huart5.Instance = UART5;
  huart5.Init.BaudRate = 115200;
  huart5.Init.WordLength = UART_WORDLENGTH_8B;
  huart5.Init.StopBits = UART_STOPBITS_1;
  huart5.Init.Parity = UART_PARITY_NONE;
  huart5.Init.Mode = UART_MODE_TX_RX;
  huart5.Init.HwFlowCtl = UART_HWCONTROL_NONE;
  huart5.Init.OverSampling = UART_OVERSAMPLING_16;
  if (HAL_UART_Init(&huart5) != HAL_OK)
  {
    Error_Handler();
  }

}

static void MX_WWDG_Init(void)
{

  hwwdg.Instance = WWDG;
  hwwdg.Init.Prescaler = WWDG_PRESCALER_1;
  hwwdg.Init.Window = 64;
  hwwdg.Init.Counter = 64;
  hwwdg.Init.EWIMode = WWDG_EWI_DISABLE;
  if (HAL_WWDG_Init(&hwwdg) != HAL_OK)
  {
    Error_Handler();
  }

}

static void MX_GPIO_Init(void)
{
  GPIO_InitTypeDef GPIO_InitStruct = {0};

  /* GPIO Ports Clock Enable */
  __HAL_RCC_GPIOE_CLK_ENABLE();
  __HAL_RCC_GPIOC_CLK_ENABLE();
  __HAL_RCC_GPIOF_CLK_ENABLE();
  __HAL_RCC_GPIOH_CLK_ENABLE();
  __HAL_RCC_GPIOA_CLK_ENABLE();
  __HAL_RCC_GPIOB_CLK_ENABLE();
  __HAL_RCC_GPIOG_CLK_ENABLE();
  __HAL_RCC_GPIOD_CLK_ENABLE();

  /*Configure GPIO pin Output Level */
  HAL_GPIO_WritePin(GPIOE, STOP_LAMP_Pin|VEHICLE_INLAMP1_Pin|VEHICLE_INLAMP2_Pin|BONNET_LAMP_Pin
                          |RIGHT_SIGNAL_Pin|DYH_GPIO7_Pin|FRONT_LAMP_Pin|BACK_LAMP_Pin, GPIO_PIN_RESET);

  /*Configure GPIO pin Output Level */
  HAL_GPIO_WritePin(GPIOC, LEFT_SIGNAL_Pin|GPIO_MPU6050_GYRO2_AD0_Pin, GPIO_PIN_RESET);

  /*Configure GPIO pin Output Level */
  HAL_GPIO_WritePin(GPIOF, DYH_GPIO2_Pin|DYH_GPIO3_Pin|DYH_GPIO4_Pin, GPIO_PIN_RESET);

  /*Configure GPIO pin Output Level */
  HAL_GPIO_WritePin(GPIOG, DYH_GPIO5_Pin|DYH_GPIO6_Pin|DEBUG_SET_Pin|GPIO_SX1262_TXEN_Pin
                          |GPIO_SX1262_RXEN_Pin|GPIO_SX1262_RESET_Pin|GPIO_MPU6050_GYRO1_AD0_Pin|GPIO_MPU6050_GYRORIGHT_AD0_Pin
                          |GPIO_MPU6050_GYROLEFT_Pin, GPIO_PIN_RESET);

  /*Configure GPIO pin Output Level */
  HAL_GPIO_WritePin(GPIOD, GPIO_Output_M1_S2_Pin|GPIO_Output_M1_S1_Pin|GPIO_Output_M1_S0_Pin|GPIO_Output_M0_S2_Pin
                          |GPIO_Output_M0_S1_Pin|GPIO_Output_M0_S0_Pin|GPIO_SX1262_NSS_Pin|GPIO_Output_LED_DRIVER_RESET_Pin, GPIO_PIN_RESET);

  /*Configure GPIO pins : STOP_LAMP_Pin VEHICLE_INLAMP1_Pin VEHICLE_INLAMP2_Pin BONNET_LAMP_Pin
                           RIGHT_SIGNAL_Pin DYH_GPIO7_Pin FRONT_LAMP_Pin BACK_LAMP_Pin */
  GPIO_InitStruct.Pin = STOP_LAMP_Pin|VEHICLE_INLAMP1_Pin|VEHICLE_INLAMP2_Pin|BONNET_LAMP_Pin
                          |RIGHT_SIGNAL_Pin|DYH_GPIO7_Pin|FRONT_LAMP_Pin|BACK_LAMP_Pin;
  GPIO_InitStruct.Mode = GPIO_MODE_OUTPUT_PP;
  GPIO_InitStruct.Pull = GPIO_NOPULL;
  GPIO_InitStruct.Speed = GPIO_SPEED_FREQ_LOW;
  HAL_GPIO_Init(GPIOE, &GPIO_InitStruct);

  /*Configure GPIO pins : LEFT_SIGNAL_Pin GPIO_MPU6050_GYRO2_AD0_Pin */
  GPIO_InitStruct.Pin = LEFT_SIGNAL_Pin|GPIO_MPU6050_GYRO2_AD0_Pin;
  GPIO_InitStruct.Mode = GPIO_MODE_OUTPUT_PP;
  GPIO_InitStruct.Pull = GPIO_NOPULL;
  GPIO_InitStruct.Speed = GPIO_SPEED_FREQ_LOW;
  HAL_GPIO_Init(GPIOC, &GPIO_InitStruct);

  /*Configure GPIO pins : DYH_GPIO2_Pin DYH_GPIO3_Pin DYH_GPIO4_Pin */
  GPIO_InitStruct.Pin = DYH_GPIO2_Pin|DYH_GPIO3_Pin|DYH_GPIO4_Pin;
  GPIO_InitStruct.Mode = GPIO_MODE_OUTPUT_PP;
  GPIO_InitStruct.Pull = GPIO_NOPULL;
  GPIO_InitStruct.Speed = GPIO_SPEED_FREQ_LOW;
  HAL_GPIO_Init(GPIOF, &GPIO_InitStruct);

  /*Configure GPIO pins : DYH_GPIO5_Pin DYH_GPIO6_Pin DEBUG_SET_Pin GPIO_SX1262_TXEN_Pin
                           GPIO_SX1262_RXEN_Pin GPIO_SX1262_RESET_Pin GPIO_MPU6050_GYRO1_AD0_Pin GPIO_MPU6050_GYRORIGHT_AD0_Pin
                           GPIO_MPU6050_GYROLEFT_Pin */
  GPIO_InitStruct.Pin = DYH_GPIO5_Pin|DYH_GPIO6_Pin|DEBUG_SET_Pin|GPIO_SX1262_TXEN_Pin
                          |GPIO_SX1262_RXEN_Pin|GPIO_SX1262_RESET_Pin|GPIO_MPU6050_GYRO1_AD0_Pin|GPIO_MPU6050_GYRORIGHT_AD0_Pin
                          |GPIO_MPU6050_GYROLEFT_Pin;
  GPIO_InitStruct.Mode = GPIO_MODE_OUTPUT_PP;
  GPIO_InitStruct.Pull = GPIO_NOPULL;
  GPIO_InitStruct.Speed = GPIO_SPEED_FREQ_LOW;
  HAL_GPIO_Init(GPIOG, &GPIO_InitStruct);

  /*Configure GPIO pin : DYH_BUSY_INPUT_Pin */
  GPIO_InitStruct.Pin = DYH_BUSY_INPUT_Pin;
  GPIO_InitStruct.Mode = GPIO_MODE_INPUT;
  GPIO_InitStruct.Pull = GPIO_NOPULL;
  HAL_GPIO_Init(DYH_BUSY_INPUT_GPIO_Port, &GPIO_InitStruct);

  /*Configure GPIO pins : GPIO_Output_M1_S2_Pin GPIO_Output_M1_S1_Pin GPIO_Output_M1_S0_Pin GPIO_Output_M0_S2_Pin
                           GPIO_Output_M0_S1_Pin GPIO_Output_M0_S0_Pin GPIO_SX1262_NSS_Pin GPIO_Output_LED_DRIVER_RESET_Pin */
  GPIO_InitStruct.Pin = GPIO_Output_M1_S2_Pin|GPIO_Output_M1_S1_Pin|GPIO_Output_M1_S0_Pin|GPIO_Output_M0_S2_Pin
                          |GPIO_Output_M0_S1_Pin|GPIO_Output_M0_S0_Pin|GPIO_SX1262_NSS_Pin|GPIO_Output_LED_DRIVER_RESET_Pin;
  GPIO_InitStruct.Mode = GPIO_MODE_OUTPUT_PP;
  GPIO_InitStruct.Pull = GPIO_NOPULL;
  GPIO_InitStruct.Speed = GPIO_SPEED_FREQ_LOW;
  HAL_GPIO_Init(GPIOD, &GPIO_InitStruct);

  /*Configure GPIO pins : EXTI3_SX1262_DIO2_Pin EXTI4_SX1262_DIO1_Pin EXTI9_MPU6050_GYRO1_Pin EXT11_MPU5060_GYRORIGHT_Pin
                           EXTI13_MPU6050_GYROLEFT_Pin */
  GPIO_InitStruct.Pin = EXTI3_SX1262_DIO2_Pin|EXTI4_SX1262_DIO1_Pin|EXTI9_MPU6050_GYRO1_Pin|EXT11_MPU5060_GYRORIGHT_Pin
                          |EXTI13_MPU6050_GYROLEFT_Pin;
  GPIO_InitStruct.Mode = GPIO_MODE_IT_RISING;
  GPIO_InitStruct.Pull = GPIO_NOPULL;
  HAL_GPIO_Init(GPIOG, &GPIO_InitStruct);

  /*Configure GPIO pin : SX1262_BUSY_INPUT_Pin */
  GPIO_InitStruct.Pin = SX1262_BUSY_INPUT_Pin;
  GPIO_InitStruct.Mode = GPIO_MODE_INPUT;
  GPIO_InitStruct.Pull = GPIO_NOPULL;
  HAL_GPIO_Init(SX1262_BUSY_INPUT_GPIO_Port, &GPIO_InitStruct);

  /*Configure GPIO pin : EXTI7_MPU6050_GYRO2_Pin */
  GPIO_InitStruct.Pin = EXTI7_MPU6050_GYRO2_Pin;
  GPIO_InitStruct.Mode = GPIO_MODE_IT_RISING;
  GPIO_InitStruct.Pull = GPIO_NOPULL;
  HAL_GPIO_Init(EXTI7_MPU6050_GYRO2_GPIO_Port, &GPIO_InitStruct);

  /*Configure GPIO pin : EXTI0_IGN_KEY_Pin */
  GPIO_InitStruct.Pin = EXTI0_IGN_KEY_Pin;
  GPIO_InitStruct.Mode = GPIO_MODE_IT_RISING;
  GPIO_InitStruct.Pull = GPIO_NOPULL;
  HAL_GPIO_Init(EXTI0_IGN_KEY_GPIO_Port, &GPIO_InitStruct);

  /*Configure GPIO pin : EXTI8_RIGHTARM_Pin */
  GPIO_InitStruct.Pin = EXTI8_RIGHTARM_Pin;
  GPIO_InitStruct.Mode = GPIO_MODE_IT_RISING;
  GPIO_InitStruct.Pull = GPIO_NOPULL;
  HAL_GPIO_Init(EXTI8_RIGHTARM_GPIO_Port, &GPIO_InitStruct);

  /*Configure GPIO pin : GPIO_LEFTARM_INPUT_Pin */
  GPIO_InitStruct.Pin = GPIO_LEFTARM_INPUT_Pin;
  GPIO_InitStruct.Mode = GPIO_MODE_INPUT;
  GPIO_InitStruct.Pull = GPIO_NOPULL;
  HAL_GPIO_Init(GPIO_LEFTARM_INPUT_GPIO_Port, &GPIO_InitStruct);

  /* EXTI interrupt init*/
  HAL_NVIC_SetPriority(EXTI0_IRQn, 5, 0);
  HAL_NVIC_EnableIRQ(EXTI0_IRQn);

  HAL_NVIC_SetPriority(EXTI3_IRQn, 5, 0);
  HAL_NVIC_EnableIRQ(EXTI3_IRQn);

  HAL_NVIC_SetPriority(EXTI4_IRQn, 5, 0);
  HAL_NVIC_EnableIRQ(EXTI4_IRQn);

  HAL_NVIC_SetPriority(EXTI9_5_IRQn, 5, 0);
  HAL_NVIC_EnableIRQ(EXTI9_5_IRQn);

  HAL_NVIC_SetPriority(EXTI15_10_IRQn, 5, 0);
  HAL_NVIC_EnableIRQ(EXTI15_10_IRQn);

}

void StartDefaultTask(void *argument)
{
  for(;;)
  {
    osDelay(1);
  }
}

void Error_Handler(void)
{
  __disable_irq();
  while (1)
  {
  }
}
